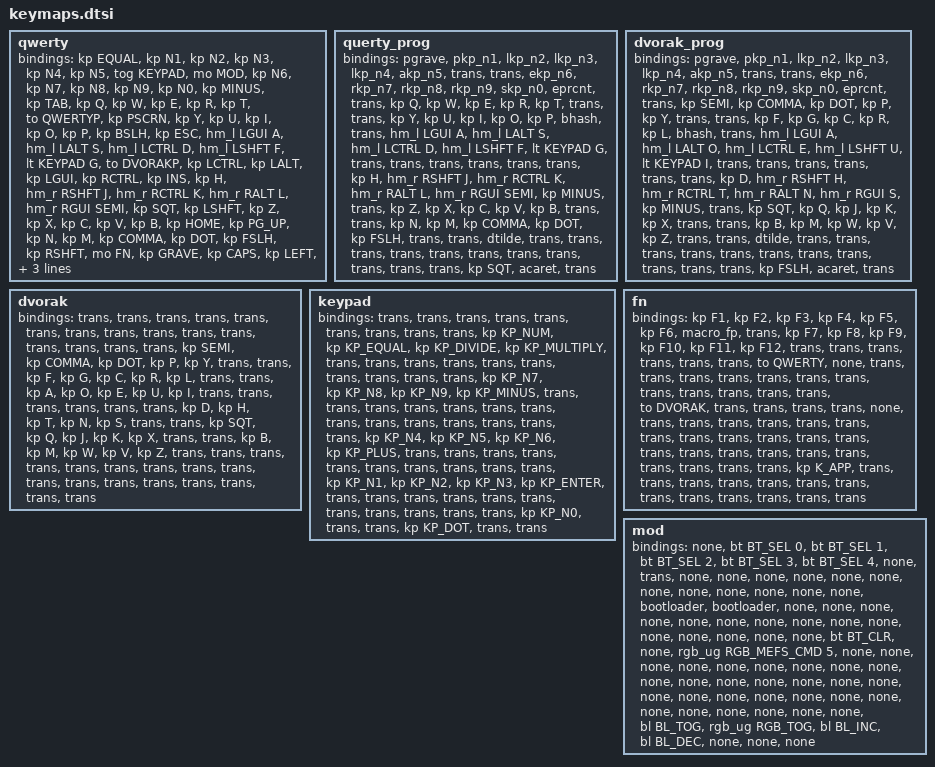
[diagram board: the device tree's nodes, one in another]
/// +-----+-----+-----+-----+-----+-----+-----+   +-----+-----+-----+-----+-----+-----+-----+
/// |     |     |     |     |     |     |     |   |     |     |     |     |     |     |     |
/// +-----+-----+-----+-----+-----+-----+-----+   +-----+-----+-----+-----+-----+-----+-----+
/// |     |     |     |     |     |     |     |   |     |     |     |     |     |     |     |
/// +-----+-----+-----+-----+-----+-----+-----+   +-----+-----+-----+-----+-----+-----+-----+
/// |     |     |     |     |     |     |     |   |     |     |     |     |     |     |     |
/// +-----+-----+-----+-----+-----+-----+-----+   +-----+-----+-----+-----+-----+-----+-----+
/// |     |     |     |     |     |     |               |     |     |     |     |     |     |
/// +-----+-----+-----+-----+-----+-----+               +-----+-----+-----+-----+-----+-----+
/// |     |     |     |     |     |                           |     |     |     |     |     |
/// +-----+-----+-----+-----+-----+                           +-----+-----+-----+-----+-----+
///
///                         +-----+-----+               +-----+-----+
///                         |     |     |               |     |     |
///                   +-----+-----+-----+               +-----+-----+-----+
///                   |     |     |     |               |     |     |     |
///                   +     +     +-----+               +-----+     +     +
///                   |     |     |     |               |     |     |     |
///                   +-----+-----+-----+               +-----+-----+-----+

qwerty {
  bindings = <
    &kp EQUAL  &kp N1        &kp N2        &kp N3         &kp N4         &kp N5        &tog KEYPAD                                                 &mo MOD    &kp N6  &kp N7         &kp N8         &kp N9        &kp N0           &kp MINUS
    &kp TAB    &kp Q         &kp W         &kp E          &kp R          &kp T         &to QWERTYP                                                 &kp PSCRN  &kp Y   &kp U          &kp I          &kp O         &kp P            &kp BSLH
    &kp ESC    &hm_l LGUI A  &hm_l LALT S  &hm_l LCTRL D  &hm_l LSHFT F  &lt KEYPAD G  &to DVORAKP  &kp LCTRL  &kp LALT      &kp LGUI   &kp RCTRL  &kp INS    &kp H   &hm_r RSHFT J  &hm_r RCTRL K  &hm_r RALT L  &hm_r RGUI SEMI  &kp SQT
    &kp LSHFT  &kp Z         &kp X         &kp C          &kp V          &kp B                                 &kp HOME      &kp PG_UP                        &kp N   &kp M          &kp COMMA      &kp DOT       &kp FSLH         &kp RSHFT
    &mo FN     &kp GRAVE     &kp CAPS      &kp LEFT       &kp RIGHT                    &kp BSPC     &kp DEL    &kp END       &kp PG_DN  &kp ENTER  &kp SPACE          &kp UP         &kp DOWN       &kp LBKT      &kp RBKT         &mo FN
  >;
};

querty_prog {
  bindings = <
    &pgrave  &pkp_n1       &lkp_n2       &lkp_n3        &lkp_n4        &akp_n5       &trans                                      &trans  &ekp_n6  &rkp_n7        &rkp_n8        &rkp_n9       &skp_n0          &eprcnt
    &trans   &kp Q         &kp W         &kp E          &kp R          &kp T         &trans                                      &trans  &kp Y    &kp U          &kp I          &kp O         &kp P            &bhash
    &trans   &hm_l LGUI A  &hm_l LALT S  &hm_l LCTRL D  &hm_l LSHFT F  &lt KEYPAD G  &trans  &trans  &trans      &trans  &trans  &trans  &kp H    &hm_r RSHFT J  &hm_r RCTRL K  &hm_r RALT L  &hm_r RGUI SEMI  &kp MINUS
    &trans   &kp Z         &kp X         &kp C          &kp V          &kp B                         &trans      &trans                  &kp N    &kp M          &kp COMMA      &kp DOT       &kp FSLH         &trans
    &trans   &dtilde       &trans        &trans         &trans                       &trans  &trans  &trans      &trans  &trans  &trans           &trans         &trans         &kp SQT       &acaret          &trans
  >;
};

dvorak_prog {
  bindings = <
    &pgrave  &pkp_n1       &lkp_n2       &lkp_n3        &lkp_n4        &akp_n5       &trans                                      &trans  &ekp_n6  &rkp_n7        &rkp_n8        &rkp_n9       &skp_n0       &eprcnt
    &trans   &kp SEMI      &kp COMMA     &kp DOT        &kp P          &kp Y         &trans                                      &trans  &kp F    &kp G          &kp C          &kp R         &kp L         &bhash
    &trans   &hm_l LGUI A  &hm_l LALT O  &hm_l LCTRL E  &hm_l LSHFT U  &lt KEYPAD I  &trans  &trans  &trans      &trans  &trans  &trans  &kp D    &hm_r RSHFT H  &hm_r RCTRL T  &hm_r RALT N  &hm_r RGUI S  &kp MINUS
    &trans   &kp SQT       &kp Q         &kp J          &kp K          &kp X                         &trans      &trans                  &kp B    &kp M          &kp W          &kp V         &kp Z         &trans
    &trans   &dtilde       &trans        &trans         &trans                       &trans  &trans  &trans      &trans  &trans  &trans           &trans         &trans         &kp FSLH      &acaret       &trans
  >;
};

dvorak {
  bindings = <
    &trans     &trans        &trans        &trans         &trans         &trans        &trans                                      &trans  &trans   &trans         &trans         &trans        &trans        &trans
    &trans     &kp SEMI      &kp COMMA     &kp DOT        &kp P          &kp Y         &trans                                      &trans  &kp F    &kp G          &kp C          &kp R         &kp L         &trans
    &trans     &kp A         &kp O         &kp E          &kp U          &kp I         &trans  &trans  &trans      &trans  &trans  &trans  &kp D    &kp H          &kp T          &kp N         &kp S         &trans
    &trans     &kp SQT       &kp Q         &kp J          &kp K          &kp X                         &trans      &trans                  &kp B    &kp M          &kp W          &kp V         &kp Z         &trans
    &trans     &trans        &trans        &trans         &trans                       &trans  &trans  &trans      &trans  &trans  &trans           &trans         &trans         &trans        &trans        &trans
  >;
};

keypad {
  bindings = <
    &trans  &trans  &trans  &trans  &trans  &trans  &trans                                      &trans     &trans  &kp KP_NUM  &kp KP_EQUAL  &kp KP_DIVIDE  &kp KP_MULTIPLY  &trans
    &trans  &trans  &trans  &trans  &trans  &trans  &trans                                      &trans     &trans  &kp KP_N7   &kp KP_N8     &kp KP_N9      &kp KP_MINUS     &trans
    &trans  &trans  &trans  &trans  &trans  &trans  &trans  &trans  &trans      &trans  &trans  &trans     &trans  &kp KP_N4   &kp KP_N5     &kp KP_N6      &kp KP_PLUS      &trans
    &trans  &trans  &trans  &trans  &trans  &trans                  &trans      &trans                     &trans  &kp KP_N1   &kp KP_N2     &kp KP_N3      &kp KP_ENTER     &trans
    &trans  &trans  &trans  &trans  &trans          &trans  &trans  &trans      &trans  &trans  &kp KP_N0          &trans      &trans        &kp KP_DOT     &trans           &trans
  >;
};

fn {
  bindings = <
    &kp F1  &kp F2  &kp F3     &kp F4         &kp F5          &kp F6  &macro_fp                                           &trans  &kp F7  &kp F8  &kp F9  &kp F10  &kp F11  &kp F12
    &trans  &trans  &trans     &trans         &trans          &trans  &to QWERTY                                       &none  &trans  &trans  &trans  &trans   &trans   &trans
    &trans  &trans  &trans     &trans         &trans          &trans  &to DVORAK  &trans  &trans      &trans  &trans  &none  &trans  &trans  &trans  &trans   &trans   &trans
    &trans  &trans  &trans     &trans         &trans          &trans                       &trans      &trans                  &trans  &trans  &trans  &trans   &trans   &trans
    &trans  &trans  &kp K_APP  &trans         &trans                  &trans       &trans  &trans      &trans  &trans  &trans          &trans  &trans  &trans   &trans   &trans
  >;
};

mod {
  bindings = <
    &none  &bt BT_SEL 0  &bt BT_SEL 1  &bt BT_SEL 2  &bt BT_SEL 3  &bt BT_SEL 4  &none                                                  &trans                  &none  &none      &none      &none  &none  &none
    &none  &none        &none        &none        &none        &none        &bootloader                                             &bootloader             &none  &none      &none      &none  &none  &none
    &none  &none        &none        &none        &none        &none        &none       &none  &none     &bt BT_CLR  &none      &rgb_ug RGB_MEFS_CMD 5  &none  &none      &none      &none  &none  &none
    &none  &none        &none        &none        &none        &none                             &none     &none                                          &none  &none      &none      &none  &none  &none
    &none  &none        &none        &none        &none                      &none       &none  &none     &none      &bl BL_TOG  &rgb_ug RGB_TOG                 &bl BL_INC  &bl BL_DEC  &none  &none  &none
  >;
};
